# ATSAML11D16A device description
Architecture: CORTEX-M23; Family: SAML; Series: SAML11
Registers are 32-bit, read-write, reset 0x0 unless marked. A register's access mark holds for its fields unless they carry their own. Offsets are from the block's base; [hi:lo] are bit positions; 'fields as' and 'values as' point back to an identical list.

## OPAMP — Operational Amplifier
Instances: OPAMP 0x42003000
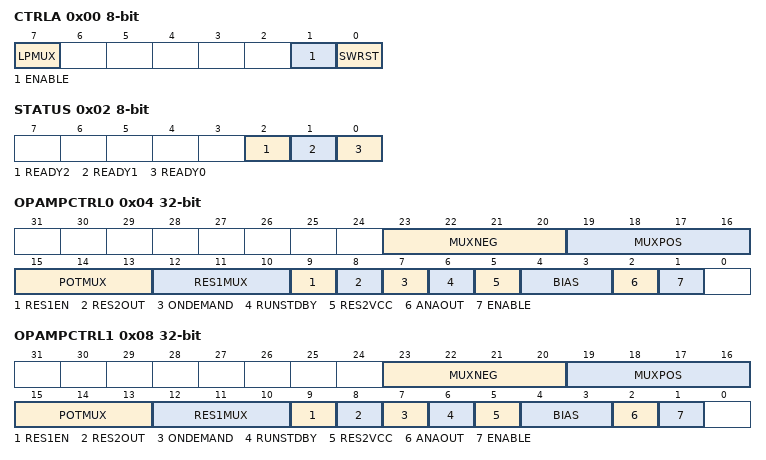
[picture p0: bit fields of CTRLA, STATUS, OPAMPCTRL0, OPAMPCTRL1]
0x00 CTRLA 8-bit — Control A
  [7] LPMUX — Low-Power Mux
  [1] ENABLE
  [0] SWRST — Software Reset
0x02 STATUS 8-bit ro
  [2] READY2 — OPAMP 2 Ready
  [1] READY1 — OPAMP 1 Ready
  [0] READY0 — OPAMP 0 Ready
0x04 OPAMPCTRL0 — OPAMP0 Control
  [23:20] MUXNEG — Negative Input Mux Selection
    0=OA0NEG (Negative I/O pin); 1=OA0TAP (Resistor ladder 0 taps); 2=REFERENCE_DAC (REFERENCE or DAC output); 3=OA0OUT (OPAMP0 output)
  [19:16] MUXPOS — Positive Input Mux Selection
    0=OA0POS (Positive I/O pin); 1=OA0TAP (Resistor ladder 0 taps); 2=REFERENCE_DAC (REFERENCE or DAC output); 3=GND (Ground)
  [15:13] POTMUX — Potentiometer Selection
    0=14R_2R (R1 = 14R, R2 = 2R); 1=12R_4R (R1 = 12R, R2 = 4R); 2=8R_8R (R1 = 8R, R2 = 8R); 3=6R_10R (R1 = 6R, R2 = 10R); 4=4R_12R (R1 = 4R, R2 = 12R); 5=3R_13R (R1 = 3R, R2 = 13R); 6=2R_14R (R1 = 2R, R2 = 14R); 7=R_15R (R1 = 1R, R2 = 15R)
  [12:10] RES1MUX — Resistor 1 Mux
    0=OAxPOS (Positive inout of OPAMPx); 1=OAxNEG (Negative input of OPAMPx); 2=DAC (DAC output); 3=GND (Ground); 4=RG_CONN
  [9] RES1EN — Resistor 1 Enable
  [8] RES2OUT — Resistor ladder To Output
  [7] ONDEMAND — On Demand Control
  [6] RUNSTDBY — Run in Standby
  [5] RES2VCC — Resistor ladder To VCC
  [4:3] BIAS — Bias Selection
  [2] ANAOUT — Analog Output
  [1] ENABLE — Operational Amplifier Enable
0x08 OPAMPCTRL1 — OPAMP1 Control
  [23:20] MUXNEG — Negative Input Mux Selection
    values as OPAMPCTRL0.MUXNEG
  [19:16] MUXPOS — Positive Input Mux Selection
    0=OA1POS (Positive I/O pin); 1=OA1TAP (Resistor ladder 1 taps); 2=REFERENCE_DAC (REFERENCE or DAC output); 3=GND (Ground); 4=OA0OUT (OPAMP0 output)
  [15:13] POTMUX — Potentiometer Selection
    values as OPAMPCTRL0.POTMUX
  [12:10] RES1MUX — Resistor 1 Mux
    0=OAxPOS (Positive inout of OPAMPx); 1=OAxNEG (Negative input of OPAMPx); 2=OA0OUT (OPAMP0 output); 3=GND (Ground); 4=RG_CONN
  [9] RES1EN — Resistor 1 Enable
  [8] RES2OUT — Resistor ladder To Output
  [7] ONDEMAND — On Demand Control
  [6] RUNSTDBY — Run in Standby
  [5] RES2VCC — Resistor ladder To VCC
  [4:3] BIAS — Bias Selection
  [2] ANAOUT — Analog Output
  [1] ENABLE — Operational Amplifier Enable
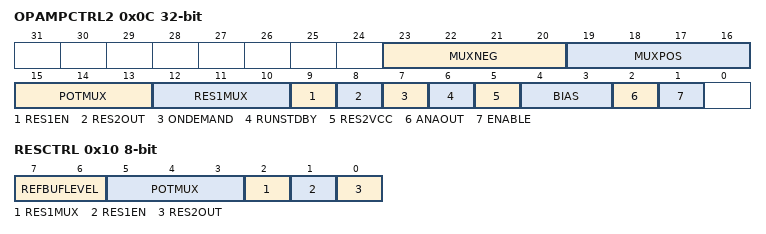
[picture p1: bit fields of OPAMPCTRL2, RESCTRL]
0x0C OPAMPCTRL2 — OPAMP2 Control
  [23:20] MUXNEG — Negative Input Mux Selection
    values as OPAMPCTRL0.MUXNEG
  [19:16] MUXPOS — Positive Input Mux Selection
    0=OA2POS (Positive I/O pin); 1=OA2TAP (Resistor ladder 2 taps); 2=REFERENCE_DAC (REFERENCE or DAC output); 3=GND (Ground); 4=OA1OUT (OPAMP1 output); 5=OA0POS (Positive I/O pin OPA0); 6=OA1POS (Positive I/O pin OPA1); 7=OA0TAP (OPAMP0 Resistor Ladder Taps); 7=RES3TAP (Resistor ladder 3 taps)
  [15:13] POTMUX — Potentiometer Selection
    values as OPAMPCTRL0.POTMUX
  [12:10] RES1MUX — Resistor 1 Mux
    0=OAxPOS (Positive inout of OPAMPx); 1=OAxNEG (Negative input of OPAMPx); 2=OA1OUT (OPAMP1 output); 3=GND (Ground)
  [9] RES1EN — Resistor 1 Enable
  [8] RES2OUT — Resistor ladder To Output
  [7] ONDEMAND — On Demand Control
  [6] RUNSTDBY — Run in Standby
  [5] RES2VCC — Resistor ladder To VCC
  [4:3] BIAS — Bias Selection
  [2] ANAOUT — Analog Output
  [1] ENABLE — Operational Amplifier Enable
0x10 RESCTRL 8-bit — Resister Control
  [7:6] REFBUFLEVEL — Reference output voltage level select
    0=1_1v; 1=1_25v; 2=1_6v
  [5:3] POTMUX — Potentiometer Selection
    0=14R_2R (Gain = 0.14); 1=12R_4R (Gain = 0.33); 2=8R_8R (Gain = 1); 3=6R_10R (Gain = 1.67); 4=4R_12R (Gain = 3); 5=3R_13R (Gain = 4.33); 6=2R_14R (Gain = 7); 7=R_15R (Gain = 15)
  [2] RES1MUX — Resistor 1 Mux
    0=DAC (DAC output); 1=REFBUF (REFERENCE output)
  [1] RES1EN — Resistor 1 Enable
  [0] RES2OUT — Resistor ladder To Output
Value list OPAMP_OPAMPCTRL__BIAS: 0=MODE0 (Minimum current consumption, but the slowest mode); 1=MODE1 (Low current consumption, slow speed); 2=MODE2 (High current consumption, fast speed); 3=MODE3 (Maximum current consumption but the fastest mode)
Value list OPAMP_OPAMPCTRL1__MUXNEG: 0=OA1NEG (Negative I/O pin); 1=OA1TAP (Resistor ladder 1 taps); 2=REFERENCE_DAC (REFERENCE or DAC output); 3=OA1OUT (OPAMP1 output)
Value list OPAMP_OPAMPCTRL2__MUXNEG: 0=OA2NEG (Negative I/O pin); 1=OA2TAP (Resistor ladder 2 taps); 2=REFERENCE_DAC (REFERENCE or DAC output); 3=OA2OUT (OPAMP2 output); 4=OA0NEG (Negative I/O pin OPA0); 5=OA1NEG (Negative I/O pin OPA1)

## Notices in the file
Copyright (c) 2019 Microchip Technology Inc.
SPDX-License-Identifier: Apache-2.0
Licensed under the Apache License, Version 2.0 (the "License");
you may not use this file except in compliance with the License.
You may obtain a copy of the License at
http://www.apache.org/licenses/LICENSE-2.0
Unless required by applicable law or agreed to in writing, software
distributed under the License is distributed on an "AS IS" BASIS,
WITHOUT WARRANTIES OR CONDITIONS OF ANY KIND, either express or implied.
See the License for the specific language governing permissions and
limitations under the License.
